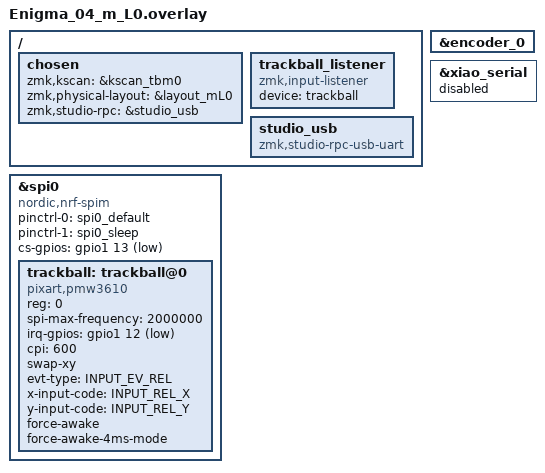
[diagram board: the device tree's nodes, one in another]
#include <input/processors.dtsi>
#include <dt-bindings/zmk/input_transform.h>
#include <zephyr/dt-bindings/input/input-event-codes.h>
#include "Enigma_04.dtsi"
#include "Enigma_04_tbm_pinctrl.dtsi"
#include "Enigma_04_tbm_layouts.dtsi"

/ {
    chosen {
        zmk,kscan = &kscan_tbm0;
        zmk,physical-layout = &layout_mL0;
        zmk,studio-rpc = &studio_usb;
    };

    trackball_listener: trackball_listener {
        compatible = "zmk,input-listener";
        device = <&trackball>;
    };

    studio_usb: studio_usb {
        compatible = "zmk,studio-rpc-usb-uart";
    };
};

&encoder_0 {
    status = "okay";
};

&xiao_serial { 
    status = "disabled"; 
};

&spi0 {
    status = "okay";
    compatible = "nordic,nrf-spim";
    pinctrl-0 = <&spi0_default>;
    pinctrl-1 = <&spi0_sleep>;
    pinctrl-names = "default", "sleep";
    cs-gpios = <&gpio1 13 GPIO_ACTIVE_LOW>; //NCS

    trackball: trackball@0 {
        status = "okay";
        compatible = "pixart,pmw3610";
        reg = <0>;
        spi-max-frequency = <2000000>;
        irq-gpios = <&gpio1 12 (GPIO_ACTIVE_LOW | GPIO_PULL_UP)>; //MOT
        cpi = <600>;
        swap-xy; /* optional */
        // invert-x; /* optional */
        // invert-y; /* optional */
        evt-type = <INPUT_EV_REL>;
        x-input-code = <INPUT_REL_X>;
        y-input-code = <INPUT_REL_Y>;

        force-awake;
        /* keep the sensor awake while ZMK activity state is ACTIVE,
           fallback to normal downshift mode after ZMK goes into IDLE / SLEEP mode.
           thus, the sensor would be a `wakeup-source` */

        force-awake-4ms-mode;
        /* while force-awake is acitvated, enable this mode to force sampling per 
           4ms, where the default sampling rate is 8ms. */
        /* NOTE: apply this mode if you need 250Hz with direct USB connection. */
    };
};
